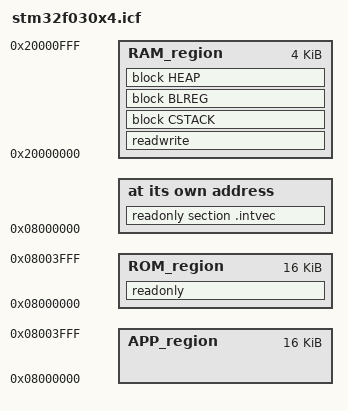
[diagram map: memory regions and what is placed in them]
/*###ICF### Section handled by ICF editor, don't touch! ****/
/*-Editor annotation file-*/
/* IcfEditorFile="$TOOLKIT_DIR$\config\ide\IcfEditor\cortex_v1_0.xml" */
/*-Specials-*/
define symbol __ICFEDIT_intvec_start__ = 0x08000000;
/*-Memory Regions-*/
define symbol __ICFEDIT_region_BOOTLOADER_start__ = 0x08000000;
define symbol __ICFEDIT_region_BOOTLOADER_end__   = 0x08000FFF;
define symbol _region_APP_start__ = 0x08000000;
define symbol _region_APP_end__   = 0x08003FFF;
define symbol __ICFEDIT_region_ROM_start__ = 0x08000000;
define symbol __ICFEDIT_region_ROM_end__   = 0x08003FFF;
define symbol __ICFEDIT_region_RAM_start__ = 0x20000000;
define symbol __ICFEDIT_region_RAM_end__   = 0x20000FFF;
/*-Sizes-*/
define symbol __ICFEDIT_size_cstack__ = 0x7F8;
define symbol __ICFEDIT_size_blreg__  = 0x008;
define symbol __ICFEDIT_size_heap__   = 0x7FF;
/**** End of ICF editor section. ###ICF###*/

define memory mem with size = 4G;
define region APP_region   = mem:[from _region_APP_start__   to _region_APP_end__];

define region ROM_region   = mem:[from _region_APP_start__   to _region_APP_end__];
define region RAM_region   = mem:[from __ICFEDIT_region_RAM_start__   to __ICFEDIT_region_RAM_end__];

define block CSTACK    with alignment = 8, size = __ICFEDIT_size_cstack__   { };
define block HEAP      with alignment = 8, size = __ICFEDIT_size_heap__     { };
define block BLREG  with alignment = 8, size = __ICFEDIT_size_blreg__     {section blreg_section };


initialize by copy { readwrite };
do not initialize  { section .noinit , section blreg_section};

place at address mem:_region_APP_start__ { readonly section .intvec };
place in ROM_region   { readonly};
place in RAM_region   { readwrite,
                        block CSTACK,block BLREG, block HEAP };
                        
export symbol _region_APP_start__;
export symbol __ICFEDIT_region_RAM_start__;
export symbol __ICFEDIT_region_RAM_end__;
